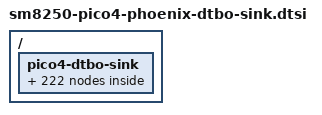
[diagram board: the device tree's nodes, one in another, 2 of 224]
// SPDX-License-Identifier: GPL-2.0-only
// Generated by dtbo_sink.py: absorbs the ABL's board overlay.

/ {
	pico4-dtbo-sink {
		pico4,refs = <&dtbo_BOB &dtbo_CPU4 &dtbo_CPU7 &dtbo_S4A &dtbo_apps_rsc &dtbo_apps_smmu &dtbo_arch_timer &dtbo_audio_apr &dtbo_bolero &dtbo_bt_en_sleep &dtbo_cam_cci0 &dtbo_cam_cci1 &dtbo_cam_sensor_6dof_vana_active &dtbo_cam_sensor_6dof_vana_suspend &dtbo_cam_sensor_6dof_vdig_active &dtbo_cam_sensor_6dof_vdig_suspend &dtbo_cam_sensor_6dof_vio_active &dtbo_cam_sensor_6dof_vio_suspend &dtbo_cam_sensor_active_3 &dtbo_cam_sensor_active_6 &dtbo_cam_sensor_active_6dofleft &dtbo_cam_sensor_active_6dofright &dtbo_cam_sensor_active_etleft &dtbo_cam_sensor_active_etright &dtbo_cam_sensor_active_rear &dtbo_cam_sensor_active_rear_aux &dtbo_cam_sensor_active_rgbleft &dtbo_cam_sensor_active_rgbright &dtbo_cam_sensor_active_rst2 &dtbo_cam_sensor_et_vana_active &dtbo_cam_sensor_et_vana_suspend &dtbo_cam_sensor_et_vio_active &dtbo_cam_sensor_et_vio_suspend &dtbo_cam_sensor_mclk0_active &dtbo_cam_sensor_mclk0_suspend &dtbo_cam_sensor_mclk1_active &dtbo_cam_sensor_mclk1_suspend &dtbo_cam_sensor_mclk2_active &dtbo_cam_sensor_mclk2_suspend &dtbo_cam_sensor_mclk3_active &dtbo_cam_sensor_mclk3_suspend &dtbo_cam_sensor_mclk4_active &dtbo_cam_sensor_mclk4_suspend &dtbo_cam_sensor_mclk5_active &dtbo_cam_sensor_mclk5_suspend &dtbo_cam_sensor_mclk6_active &dtbo_cam_sensor_mclk6_suspend &dtbo_cam_sensor_rgb_vana_active &dtbo_cam_sensor_rgb_vana_suspend &dtbo_cam_sensor_rgb_vdig_active &dtbo_cam_sensor_rgb_vdig_suspend &dtbo_cam_sensor_rgb_vio_active &dtbo_cam_sensor_rgb_vio_suspend &dtbo_cam_sensor_suspend_3 &dtbo_cam_sensor_suspend_6 &dtbo_cam_sensor_suspend_6dofleft &dtbo_cam_sensor_suspend_6dofright &dtbo_cam_sensor_suspend_etleft &dtbo_cam_sensor_suspend_etright &dtbo_cam_sensor_suspend_rear &dtbo_cam_sensor_suspend_rear_aux &dtbo_cam_sensor_suspend_rgbleft &dtbo_cam_sensor_suspend_rgbright &dtbo_cam_sensor_suspend_rst2 &dtbo_clock_camcc &dtbo_clock_rpmh &dtbo_cpu4_isolate &dtbo_cpu5_isolate &dtbo_cpu6_isolate &dtbo_cpu7_isolate &dtbo_dai_mi2s0 &dtbo_dai_mi2s2 &dtbo_dai_mi2s3 &dtbo_dwc1 &dtbo_eud &dtbo_fsa4480 &dtbo_intc &dtbo_ipa_hw &dtbo_kona_snd &dtbo_lpass_audio_hw_vote &dtbo_lpass_core_hw_vote &dtbo_lt9611_pins &dtbo_mdm0 &dtbo_mdss_dsi0 &dtbo_mdss_dsi0_pll &dtbo_mdss_dsi1 &dtbo_mdss_dsi1_pll &dtbo_mdss_dsi_phy0 &dtbo_mdss_dsi_phy1 &dtbo_mdss_mdp &dtbo_memtimer &dtbo_mhi_0 &dtbo_modem_mmw_skin0 &dtbo_modem_mmw_skin1 &dtbo_modem_mmw_skin2 &dtbo_modem_skin &dtbo_msm_gpu &dtbo_nfc_clk_req_active &dtbo_nfc_clk_req_suspend &dtbo_nfc_enable_active &dtbo_nfc_enable_suspend &dtbo_nfc_int_active &dtbo_nfc_int_suspend &dtbo_pcie0 &dtbo_pcie1 &dtbo_pcie2 &dtbo_pdc &dtbo_pm8009_l1 &dtbo_pm8009_l2 &dtbo_pm8009_l3 &dtbo_pm8009_l5 &dtbo_pm8009_l6 &dtbo_pm8009_l7 &dtbo_pm8009_s2 &dtbo_pm8150_l10 &dtbo_pm8150_l13 &dtbo_pm8150_l14 &dtbo_pm8150_l15 &dtbo_pm8150_l16 &dtbo_pm8150_l17 &dtbo_pm8150_l2 &dtbo_pm8150_l5 &dtbo_pm8150_l6 &dtbo_pm8150_l7 &dtbo_pm8150_l9 &dtbo_pm8150_s4 &dtbo_pm8150_s5 &dtbo_pm8150_s6 &dtbo_pm8150a_bob &dtbo_pm8150a_l1 &dtbo_pm8150a_l10 &dtbo_pm8150a_l11 &dtbo_pm8150a_l2 &dtbo_pm8150a_l3 &dtbo_pm8150a_l4 &dtbo_pm8150a_l5 &dtbo_pm8150a_l6 &dtbo_pm8150a_l7 &dtbo_pm8150a_l8 &dtbo_pm8150a_l9 &dtbo_pm8150a_s8 &dtbo_pmx_ts_release &dtbo_pri_mi2s_sck_active &dtbo_pri_mi2s_sck_sleep &dtbo_pri_mi2s_sd0_active &dtbo_pri_mi2s_sd0_sleep &dtbo_pri_mi2s_sd1_active &dtbo_pri_mi2s_sd1_sleep &dtbo_pri_mi2s_ws_active &dtbo_pri_mi2s_ws_sleep &dtbo_q6core &dtbo_qupv3_se12_2uart &dtbo_qupv3_se13_i2c &dtbo_qupv3_se15_i2c &dtbo_qupv3_se16_4uart &dtbo_qupv3_se17_i2c &dtbo_qupv3_se19_spi &dtbo_qupv3_se1_2uart &dtbo_qupv3_se1_i2c &dtbo_qupv3_se2_2uart &dtbo_qupv3_se6_4uart &dtbo_sdc2_clk_off &dtbo_sdc2_clk_on &dtbo_sdc2_cmd_off &dtbo_sdc2_cmd_on &dtbo_sdc2_data_off &dtbo_sdc2_data_on &dtbo_sde_dp &dtbo_sde_dp_aux_active_v0 &dtbo_sde_dp_aux_active_v1 &dtbo_sde_dp_aux_suspend_v0 &dtbo_sde_dp_aux_suspend_v1 &dtbo_sde_dp_usbplug_cc_active &dtbo_sde_dp_usbplug_cc_suspend &dtbo_sde_dsi1_active &dtbo_sde_dsi1_suspend &dtbo_sde_dsi_active &dtbo_sde_dsi_suspend &dtbo_sde_rscc &dtbo_sde_te1_active &dtbo_sde_te1_suspend &dtbo_sde_te_active &dtbo_sde_te_suspend &dtbo_sdhc_2 &dtbo_soc &dtbo_spkr_1_sd_n_active &dtbo_spkr_1_sd_n_sleep &dtbo_spkr_2_sd_n_active &dtbo_spkr_2_sd_n_sleep &dtbo_spmi_bus &dtbo_spmi_debug_bus &dtbo_storage_cd &dtbo_stub_codec &dtbo_tert_mi2s_sck_active &dtbo_tert_mi2s_sck_sleep &dtbo_tert_mi2s_sd0_active &dtbo_tert_mi2s_sd0_sleep &dtbo_tert_mi2s_ws_active &dtbo_tert_mi2s_ws_sleep &dtbo_thermal_zones &dtbo_titan_top_gdsc &dtbo_tlmm &dtbo_tlmm_app_key_active &dtbo_tlmm_app_key_suspend &dtbo_ts_active &dtbo_ts_int_suspend &dtbo_ts_reset_suspend &dtbo_ufs_phy_gdsc &dtbo_ufshc_mem &dtbo_ufsphy_mem &dtbo_usb0 &dtbo_usb1 &dtbo_usb2_id_det_default &dtbo_usb2_phy0 &dtbo_usb_nop_phy &dtbo_va_cdc_dma_0_tx &dtbo_vendor &dtbo_wcd938x_reset_active &dtbo_wcd938x_reset_sleep &dtbo_wdog &dtbo_wil6210 &dtbo_wlan>;

		dtbo_BOB: BOB {
		};
		dtbo_CPU4: CPU4 {
		};
		dtbo_CPU7: CPU7 {
		};
		dtbo_S4A: S4A {
		};
		dtbo_apps_rsc: apps_rsc {
		};
		dtbo_apps_smmu: apps_smmu {
		};
		dtbo_arch_timer: arch_timer {
		};
		dtbo_audio_apr: audio_apr {
		};
		dtbo_bolero: bolero {
		};
		dtbo_bt_en_sleep: bt_en_sleep {
		};
		dtbo_cam_cci0: cam_cci0 {
		};
		dtbo_cam_cci1: cam_cci1 {
		};
		dtbo_cam_sensor_6dof_vana_active: cam_sensor_6dof_vana_active {
		};
		dtbo_cam_sensor_6dof_vana_suspend: cam_sensor_6dof_vana_suspend {
		};
		dtbo_cam_sensor_6dof_vdig_active: cam_sensor_6dof_vdig_active {
		};
		dtbo_cam_sensor_6dof_vdig_suspend: cam_sensor_6dof_vdig_suspend {
		};
		dtbo_cam_sensor_6dof_vio_active: cam_sensor_6dof_vio_active {
		};
		dtbo_cam_sensor_6dof_vio_suspend: cam_sensor_6dof_vio_suspend {
		};
		dtbo_cam_sensor_active_3: cam_sensor_active_3 {
		};
		dtbo_cam_sensor_active_6: cam_sensor_active_6 {
		};
		dtbo_cam_sensor_active_6dofleft: cam_sensor_active_6dofleft {
		};
		dtbo_cam_sensor_active_6dofright: cam_sensor_active_6dofright {
		};
		dtbo_cam_sensor_active_etleft: cam_sensor_active_etleft {
		};
		dtbo_cam_sensor_active_etright: cam_sensor_active_etright {
		};
		dtbo_cam_sensor_active_rear: cam_sensor_active_rear {
		};
		dtbo_cam_sensor_active_rear_aux: cam_sensor_active_rear_aux {
		};
		dtbo_cam_sensor_active_rgbleft: cam_sensor_active_rgbleft {
		};
		dtbo_cam_sensor_active_rgbright: cam_sensor_active_rgbright {
		};
		dtbo_cam_sensor_active_rst2: cam_sensor_active_rst2 {
		};
		dtbo_cam_sensor_et_vana_active: cam_sensor_et_vana_active {
		};
		dtbo_cam_sensor_et_vana_suspend: cam_sensor_et_vana_suspend {
		};
		dtbo_cam_sensor_et_vio_active: cam_sensor_et_vio_active {
		};
		dtbo_cam_sensor_et_vio_suspend: cam_sensor_et_vio_suspend {
		};
		dtbo_cam_sensor_mclk0_active: cam_sensor_mclk0_active {
		};
		dtbo_cam_sensor_mclk0_suspend: cam_sensor_mclk0_suspend {
		};
		dtbo_cam_sensor_mclk1_active: cam_sensor_mclk1_active {
		};
		dtbo_cam_sensor_mclk1_suspend: cam_sensor_mclk1_suspend {
		};
		dtbo_cam_sensor_mclk2_active: cam_sensor_mclk2_active {
		};
		dtbo_cam_sensor_mclk2_suspend: cam_sensor_mclk2_suspend {
		};
		dtbo_cam_sensor_mclk3_active: cam_sensor_mclk3_active {
		};
		dtbo_cam_sensor_mclk3_suspend: cam_sensor_mclk3_suspend {
		};
		dtbo_cam_sensor_mclk4_active: cam_sensor_mclk4_active {
		};
		dtbo_cam_sensor_mclk4_suspend: cam_sensor_mclk4_suspend {
		};
		dtbo_cam_sensor_mclk5_active: cam_sensor_mclk5_active {
		};
		dtbo_cam_sensor_mclk5_suspend: cam_sensor_mclk5_suspend {
		};
		dtbo_cam_sensor_mclk6_active: cam_sensor_mclk6_active {
		};
		dtbo_cam_sensor_mclk6_suspend: cam_sensor_mclk6_suspend {
		};
		dtbo_cam_sensor_rgb_vana_active: cam_sensor_rgb_vana_active {
		};
		dtbo_cam_sensor_rgb_vana_suspend: cam_sensor_rgb_vana_suspend {
		};
		dtbo_cam_sensor_rgb_vdig_active: cam_sensor_rgb_vdig_active {
		};
		dtbo_cam_sensor_rgb_vdig_suspend: cam_sensor_rgb_vdig_suspend {
		};
		dtbo_cam_sensor_rgb_vio_active: cam_sensor_rgb_vio_active {
		};
		dtbo_cam_sensor_rgb_vio_suspend: cam_sensor_rgb_vio_suspend {
		};
		dtbo_cam_sensor_suspend_3: cam_sensor_suspend_3 {
		};
		dtbo_cam_sensor_suspend_6: cam_sensor_suspend_6 {
		};
		dtbo_cam_sensor_suspend_6dofleft: cam_sensor_suspend_6dofleft {
		};
		dtbo_cam_sensor_suspend_6dofright: cam_sensor_suspend_6dofright {
		};
		dtbo_cam_sensor_suspend_etleft: cam_sensor_suspend_etleft {
		};
		dtbo_cam_sensor_suspend_etright: cam_sensor_suspend_etright {
		};
		dtbo_cam_sensor_suspend_rear: cam_sensor_suspend_rear {
		};
		dtbo_cam_sensor_suspend_rear_aux: cam_sensor_suspend_rear_aux {
		};
		dtbo_cam_sensor_suspend_rgbleft: cam_sensor_suspend_rgbleft {
		};
		dtbo_cam_sensor_suspend_rgbright: cam_sensor_suspend_rgbright {
		};
		dtbo_cam_sensor_suspend_rst2: cam_sensor_suspend_rst2 {
		};
		dtbo_clock_camcc: clock_camcc {
		};
		dtbo_clock_rpmh: clock_rpmh {
		};
		dtbo_cpu4_isolate: cpu4_isolate {
		};
		dtbo_cpu5_isolate: cpu5_isolate {
		};
		dtbo_cpu6_isolate: cpu6_isolate {
		};
		dtbo_cpu7_isolate: cpu7_isolate {
		};
		dtbo_dai_mi2s0: dai_mi2s0 {
		};
		dtbo_dai_mi2s2: dai_mi2s2 {
		};
		dtbo_dai_mi2s3: dai_mi2s3 {
		};
		dtbo_dwc1: dwc1 {
		};
		dtbo_eud: eud {
		};
		dtbo_fsa4480: fsa4480 {
		};
		dtbo_intc: intc {
		};
		dtbo_ipa_hw: ipa_hw {
		};
		dtbo_kona_snd: kona_snd {
		};
		dtbo_lpass_audio_hw_vote: lpass_audio_hw_vote {
		};
		dtbo_lpass_core_hw_vote: lpass_core_hw_vote {
		};
		dtbo_lt9611_pins: lt9611_pins {
		};
		dtbo_mdm0: mdm0 {
		};
		dtbo_mdss_dsi0: mdss_dsi0 {
		};
		dtbo_mdss_dsi0_pll: mdss_dsi0_pll {
		};
		dtbo_mdss_dsi1: mdss_dsi1 {
		};
		dtbo_mdss_dsi1_pll: mdss_dsi1_pll {
		};
		dtbo_mdss_dsi_phy0: mdss_dsi_phy0 {
		};
		dtbo_mdss_dsi_phy1: mdss_dsi_phy1 {
		};
		dtbo_mdss_mdp: mdss_mdp {
		};
		dtbo_memtimer: memtimer {
		};
		dtbo_mhi_0: mhi_0 {
		};
		dtbo_modem_mmw_skin0: modem_mmw_skin0 {
		};
		dtbo_modem_mmw_skin1: modem_mmw_skin1 {
		};
		dtbo_modem_mmw_skin2: modem_mmw_skin2 {
		};
		dtbo_modem_skin: modem_skin {
		};
		dtbo_msm_gpu: msm_gpu {
		};
		dtbo_nfc_clk_req_active: nfc_clk_req_active {
		};
		dtbo_nfc_clk_req_suspend: nfc_clk_req_suspend {
		};
		dtbo_nfc_enable_active: nfc_enable_active {
		};
		dtbo_nfc_enable_suspend: nfc_enable_suspend {
		};
		dtbo_nfc_int_active: nfc_int_active {
		};
		dtbo_nfc_int_suspend: nfc_int_suspend {
		};
		dtbo_pcie0: pcie0 {
		};
		dtbo_pcie1: pcie1 {
		};
		dtbo_pcie2: pcie2 {
		};
		dtbo_pdc: pdc {
		};
		dtbo_pm8009_l1: pm8009_l1 {
		};
		dtbo_pm8009_l2: pm8009_l2 {
		};
		dtbo_pm8009_l3: pm8009_l3 {
		};
		dtbo_pm8009_l5: pm8009_l5 {
		};
		dtbo_pm8009_l6: pm8009_l6 {
		};
		dtbo_pm8009_l7: pm8009_l7 {
		};
		dtbo_pm8009_s2: pm8009_s2 {
		};
		dtbo_pm8150_l10: pm8150_l10 {
		};
		dtbo_pm8150_l13: pm8150_l13 {
		};
		dtbo_pm8150_l14: pm8150_l14 {
		};
		dtbo_pm8150_l15: pm8150_l15 {
		};
		dtbo_pm8150_l16: pm8150_l16 {
		};
		dtbo_pm8150_l17: pm8150_l17 {
		};
		dtbo_pm8150_l2: pm8150_l2 {
		};
		dtbo_pm8150_l5: pm8150_l5 {
		};
		dtbo_pm8150_l6: pm8150_l6 {
		};
		dtbo_pm8150_l7: pm8150_l7 {
		};
		dtbo_pm8150_l9: pm8150_l9 {
		};
		dtbo_pm8150_s4: pm8150_s4 {
		};
		dtbo_pm8150_s5: pm8150_s5 {
		};
		dtbo_pm8150_s6: pm8150_s6 {
		};
		dtbo_pm8150a_bob: pm8150a_bob {
		};
		dtbo_pm8150a_l1: pm8150a_l1 {
		};
		dtbo_pm8150a_l10: pm8150a_l10 {
		};
		dtbo_pm8150a_l11: pm8150a_l11 {
		};
		dtbo_pm8150a_l2: pm8150a_l2 {
		};
		dtbo_pm8150a_l3: pm8150a_l3 {
		};
		dtbo_pm8150a_l4: pm8150a_l4 {
		};
		dtbo_pm8150a_l5: pm8150a_l5 {
		};
		dtbo_pm8150a_l6: pm8150a_l6 {
		};
		dtbo_pm8150a_l7: pm8150a_l7 {
		};
		dtbo_pm8150a_l8: pm8150a_l8 {
		};
		dtbo_pm8150a_l9: pm8150a_l9 {
		};
		dtbo_pm8150a_s8: pm8150a_s8 {
		};
		dtbo_pmx_ts_release: pmx_ts_release {
		};
		dtbo_pri_mi2s_sck_active: pri_mi2s_sck_active {
		};
		dtbo_pri_mi2s_sck_sleep: pri_mi2s_sck_sleep {
		};
		dtbo_pri_mi2s_sd0_active: pri_mi2s_sd0_active {
		};
		dtbo_pri_mi2s_sd0_sleep: pri_mi2s_sd0_sleep {
		};
		dtbo_pri_mi2s_sd1_active: pri_mi2s_sd1_active {
		};
		dtbo_pri_mi2s_sd1_sleep: pri_mi2s_sd1_sleep {
		};
		dtbo_pri_mi2s_ws_active: pri_mi2s_ws_active {
		};
		dtbo_pri_mi2s_ws_sleep: pri_mi2s_ws_sleep {
		};
		dtbo_q6core: q6core {
		};
		dtbo_qupv3_se12_2uart: qupv3_se12_2uart {
		};
		dtbo_qupv3_se13_i2c: qupv3_se13_i2c {
		};
		dtbo_qupv3_se15_i2c: qupv3_se15_i2c {
		};
		dtbo_qupv3_se16_4uart: qupv3_se16_4uart {
		};
		dtbo_qupv3_se17_i2c: qupv3_se17_i2c {
		};
		dtbo_qupv3_se19_spi: qupv3_se19_spi {
		};
		dtbo_qupv3_se1_2uart: qupv3_se1_2uart {
		};
		dtbo_qupv3_se1_i2c: qupv3_se1_i2c {
		};
		dtbo_qupv3_se2_2uart: qupv3_se2_2uart {
		};
		dtbo_qupv3_se6_4uart: qupv3_se6_4uart {
		};
		dtbo_sdc2_clk_off: sdc2_clk_off {
		};
		dtbo_sdc2_clk_on: sdc2_clk_on {
		};
		dtbo_sdc2_cmd_off: sdc2_cmd_off {
		};
		dtbo_sdc2_cmd_on: sdc2_cmd_on {
		};
		dtbo_sdc2_data_off: sdc2_data_off {
		};
		dtbo_sdc2_data_on: sdc2_data_on {
		};
		dtbo_sde_dp: sde_dp {
		};
		dtbo_sde_dp_aux_active_v0: sde_dp_aux_active_v0 {
		};
		dtbo_sde_dp_aux_active_v1: sde_dp_aux_active_v1 {
		};
		dtbo_sde_dp_aux_suspend_v0: sde_dp_aux_suspend_v0 {
		};
		dtbo_sde_dp_aux_suspend_v1: sde_dp_aux_suspend_v1 {
		};
		dtbo_sde_dp_usbplug_cc_active: sde_dp_usbplug_cc_active {
		};
		dtbo_sde_dp_usbplug_cc_suspend: sde_dp_usbplug_cc_suspend {
		};
		dtbo_sde_dsi1_active: sde_dsi1_active {
		};
		dtbo_sde_dsi1_suspend: sde_dsi1_suspend {
		};
		dtbo_sde_dsi_active: sde_dsi_active {
		};
		dtbo_sde_dsi_suspend: sde_dsi_suspend {
		};
		dtbo_sde_rscc: sde_rscc {
		};
		dtbo_sde_te1_active: sde_te1_active {
		};
		dtbo_sde_te1_suspend: sde_te1_suspend {
		};
		dtbo_sde_te_active: sde_te_active {
		};
		dtbo_sde_te_suspend: sde_te_suspend {
		};
		dtbo_sdhc_2: sdhc_2 {
		};
		dtbo_soc: soc {
		};
		dtbo_spkr_1_sd_n_active: spkr_1_sd_n_active {
		};
		dtbo_spkr_1_sd_n_sleep: spkr_1_sd_n_sleep {
		};
		dtbo_spkr_2_sd_n_active: spkr_2_sd_n_active {
		};
		dtbo_spkr_2_sd_n_sleep: spkr_2_sd_n_sleep {
		};
		dtbo_spmi_bus: spmi_bus {
		};
		dtbo_spmi_debug_bus: spmi_debug_bus {
		};
		dtbo_storage_cd: storage_cd {
		};
		dtbo_stub_codec: stub_codec {
		};
		dtbo_tert_mi2s_sck_active: tert_mi2s_sck_active {
		};
		dtbo_tert_mi2s_sck_sleep: tert_mi2s_sck_sleep {
		};
		dtbo_tert_mi2s_sd0_active: tert_mi2s_sd0_active {
		};
		dtbo_tert_mi2s_sd0_sleep: tert_mi2s_sd0_sleep {
		};
		dtbo_tert_mi2s_ws_active: tert_mi2s_ws_active {
		};
		dtbo_tert_mi2s_ws_sleep: tert_mi2s_ws_sleep {
		};
		dtbo_thermal_zones: thermal_zones {
		};
		dtbo_titan_top_gdsc: titan_top_gdsc {
		};
		dtbo_tlmm: tlmm {
		};
		dtbo_tlmm_app_key_active: tlmm_app_key_active {
		};
		dtbo_tlmm_app_key_suspend: tlmm_app_key_suspend {
		};
		dtbo_ts_active: ts_active {
		};
		dtbo_ts_int_suspend: ts_int_suspend {
		};
		dtbo_ts_reset_suspend: ts_reset_suspend {
		};
		dtbo_ufs_phy_gdsc: ufs_phy_gdsc {
		};
		dtbo_ufshc_mem: ufshc_mem {
		};
		dtbo_ufsphy_mem: ufsphy_mem {
		};
		dtbo_usb0: usb0 {
		};
		dtbo_usb1: usb1 {
		};
		dtbo_usb2_id_det_default: usb2_id_det_default {
		};
		dtbo_usb2_phy0: usb2_phy0 {
		};
		dtbo_usb_nop_phy: usb_nop_phy {
		};
		dtbo_va_cdc_dma_0_tx: va_cdc_dma_0_tx {
		};
		dtbo_vendor: vendor {
		};
		dtbo_wcd938x_reset_active: wcd938x_reset_active {
		};
		dtbo_wcd938x_reset_sleep: wcd938x_reset_sleep {
		};
		dtbo_wdog: wdog {
		};
		dtbo_wil6210: wil6210 {
		};
		dtbo_wlan: wlan {
		};
	};

	__symbols__ {
		BOB = "/pico4-dtbo-sink/BOB";
		CPU4 = "/pico4-dtbo-sink/CPU4";
		CPU7 = "/pico4-dtbo-sink/CPU7";
		S4A = "/pico4-dtbo-sink/S4A";
		apps_rsc = "/pico4-dtbo-sink/apps_rsc";
		apps_smmu = "/pico4-dtbo-sink/apps_smmu";
		arch_timer = "/pico4-dtbo-sink/arch_timer";
		audio_apr = "/pico4-dtbo-sink/audio_apr";
		bolero = "/pico4-dtbo-sink/bolero";
		bt_en_sleep = "/pico4-dtbo-sink/bt_en_sleep";
		cam_cci0 = "/pico4-dtbo-sink/cam_cci0";
		cam_cci1 = "/pico4-dtbo-sink/cam_cci1";
		cam_sensor_6dof_vana_active = "/pico4-dtbo-sink/cam_sensor_6dof_vana_active";
		cam_sensor_6dof_vana_suspend = "/pico4-dtbo-sink/cam_sensor_6dof_vana_suspend";
		cam_sensor_6dof_vdig_active = "/pico4-dtbo-sink/cam_sensor_6dof_vdig_active";
		cam_sensor_6dof_vdig_suspend = "/pico4-dtbo-sink/cam_sensor_6dof_vdig_suspend";
		cam_sensor_6dof_vio_active = "/pico4-dtbo-sink/cam_sensor_6dof_vio_active";
		cam_sensor_6dof_vio_suspend = "/pico4-dtbo-sink/cam_sensor_6dof_vio_suspend";
		cam_sensor_active_3 = "/pico4-dtbo-sink/cam_sensor_active_3";
		cam_sensor_active_6 = "/pico4-dtbo-sink/cam_sensor_active_6";
		cam_sensor_active_6dofleft = "/pico4-dtbo-sink/cam_sensor_active_6dofleft";
		cam_sensor_active_6dofright = "/pico4-dtbo-sink/cam_sensor_active_6dofright";
		cam_sensor_active_etleft = "/pico4-dtbo-sink/cam_sensor_active_etleft";
		cam_sensor_active_etright = "/pico4-dtbo-sink/cam_sensor_active_etright";
		cam_sensor_active_rear = "/pico4-dtbo-sink/cam_sensor_active_rear";
		cam_sensor_active_rear_aux = "/pico4-dtbo-sink/cam_sensor_active_rear_aux";
		cam_sensor_active_rgbleft = "/pico4-dtbo-sink/cam_sensor_active_rgbleft";
		cam_sensor_active_rgbright = "/pico4-dtbo-sink/cam_sensor_active_rgbright";
		cam_sensor_active_rst2 = "/pico4-dtbo-sink/cam_sensor_active_rst2";
		cam_sensor_et_vana_active = "/pico4-dtbo-sink/cam_sensor_et_vana_active";
		cam_sensor_et_vana_suspend = "/pico4-dtbo-sink/cam_sensor_et_vana_suspend";
		cam_sensor_et_vio_active = "/pico4-dtbo-sink/cam_sensor_et_vio_active";
		cam_sensor_et_vio_suspend = "/pico4-dtbo-sink/cam_sensor_et_vio_suspend";
		cam_sensor_mclk0_active = "/pico4-dtbo-sink/cam_sensor_mclk0_active";
		cam_sensor_mclk0_suspend = "/pico4-dtbo-sink/cam_sensor_mclk0_suspend";
		cam_sensor_mclk1_active = "/pico4-dtbo-sink/cam_sensor_mclk1_active";
		cam_sensor_mclk1_suspend = "/pico4-dtbo-sink/cam_sensor_mclk1_suspend";
		cam_sensor_mclk2_active = "/pico4-dtbo-sink/cam_sensor_mclk2_active";
		cam_sensor_mclk2_suspend = "/pico4-dtbo-sink/cam_sensor_mclk2_suspend";
		cam_sensor_mclk3_active = "/pico4-dtbo-sink/cam_sensor_mclk3_active";
		cam_sensor_mclk3_suspend = "/pico4-dtbo-sink/cam_sensor_mclk3_suspend";
		cam_sensor_mclk4_active = "/pico4-dtbo-sink/cam_sensor_mclk4_active";
		cam_sensor_mclk4_suspend = "/pico4-dtbo-sink/cam_sensor_mclk4_suspend";
		cam_sensor_mclk5_active = "/pico4-dtbo-sink/cam_sensor_mclk5_active";
		cam_sensor_mclk5_suspend = "/pico4-dtbo-sink/cam_sensor_mclk5_suspend";
		cam_sensor_mclk6_active = "/pico4-dtbo-sink/cam_sensor_mclk6_active";
		cam_sensor_mclk6_suspend = "/pico4-dtbo-sink/cam_sensor_mclk6_suspend";
		cam_sensor_rgb_vana_active = "/pico4-dtbo-sink/cam_sensor_rgb_vana_active";
		cam_sensor_rgb_vana_suspend = "/pico4-dtbo-sink/cam_sensor_rgb_vana_suspend";
		cam_sensor_rgb_vdig_active = "/pico4-dtbo-sink/cam_sensor_rgb_vdig_active";
		cam_sensor_rgb_vdig_suspend = "/pico4-dtbo-sink/cam_sensor_rgb_vdig_suspend";
		cam_sensor_rgb_vio_active = "/pico4-dtbo-sink/cam_sensor_rgb_vio_active";
		cam_sensor_rgb_vio_suspend = "/pico4-dtbo-sink/cam_sensor_rgb_vio_suspend";
		cam_sensor_suspend_3 = "/pico4-dtbo-sink/cam_sensor_suspend_3";
		cam_sensor_suspend_6 = "/pico4-dtbo-sink/cam_sensor_suspend_6";
		cam_sensor_suspend_6dofleft = "/pico4-dtbo-sink/cam_sensor_suspend_6dofleft";
		cam_sensor_suspend_6dofright = "/pico4-dtbo-sink/cam_sensor_suspend_6dofright";
		cam_sensor_suspend_etleft = "/pico4-dtbo-sink/cam_sensor_suspend_etleft";
		cam_sensor_suspend_etright = "/pico4-dtbo-sink/cam_sensor_suspend_etright";
		cam_sensor_suspend_rear = "/pico4-dtbo-sink/cam_sensor_suspend_rear";
		cam_sensor_suspend_rear_aux = "/pico4-dtbo-sink/cam_sensor_suspend_rear_aux";
		cam_sensor_suspend_rgbleft = "/pico4-dtbo-sink/cam_sensor_suspend_rgbleft";
		cam_sensor_suspend_rgbright = "/pico4-dtbo-sink/cam_sensor_suspend_rgbright";
		cam_sensor_suspend_rst2 = "/pico4-dtbo-sink/cam_sensor_suspend_rst2";
		clock_camcc = "/pico4-dtbo-sink/clock_camcc";
		clock_rpmh = "/pico4-dtbo-sink/clock_rpmh";
		cpu4_isolate = "/pico4-dtbo-sink/cpu4_isolate";
		cpu5_isolate = "/pico4-dtbo-sink/cpu5_isolate";
		cpu6_isolate = "/pico4-dtbo-sink/cpu6_isolate";
		cpu7_isolate = "/pico4-dtbo-sink/cpu7_isolate";
		dai_mi2s0 = "/pico4-dtbo-sink/dai_mi2s0";
		dai_mi2s2 = "/pico4-dtbo-sink/dai_mi2s2";
		dai_mi2s3 = "/pico4-dtbo-sink/dai_mi2s3";
		dwc1 = "/pico4-dtbo-sink/dwc1";
		eud = "/pico4-dtbo-sink/eud";
		fsa4480 = "/pico4-dtbo-sink/fsa4480";
		intc = "/pico4-dtbo-sink/intc";
		ipa_hw = "/pico4-dtbo-sink/ipa_hw";
		kona_snd = "/pico4-dtbo-sink/kona_snd";
		lpass_audio_hw_vote = "/pico4-dtbo-sink/lpass_audio_hw_vote";
		lpass_core_hw_vote = "/pico4-dtbo-sink/lpass_core_hw_vote";
		lt9611_pins = "/pico4-dtbo-sink/lt9611_pins";
		mdm0 = "/pico4-dtbo-sink/mdm0";
		mdss_dsi0 = "/pico4-dtbo-sink/mdss_dsi0";
		mdss_dsi0_pll = "/pico4-dtbo-sink/mdss_dsi0_pll";
		mdss_dsi1 = "/pico4-dtbo-sink/mdss_dsi1";
		mdss_dsi1_pll = "/pico4-dtbo-sink/mdss_dsi1_pll";
		mdss_dsi_phy0 = "/pico4-dtbo-sink/mdss_dsi_phy0";
		mdss_dsi_phy1 = "/pico4-dtbo-sink/mdss_dsi_phy1";
		mdss_mdp = "/pico4-dtbo-sink/mdss_mdp";
		memtimer = "/pico4-dtbo-sink/memtimer";
		mhi_0 = "/pico4-dtbo-sink/mhi_0";
		modem_mmw_skin0 = "/pico4-dtbo-sink/modem_mmw_skin0";
		modem_mmw_skin1 = "/pico4-dtbo-sink/modem_mmw_skin1";
		modem_mmw_skin2 = "/pico4-dtbo-sink/modem_mmw_skin2";
		modem_skin = "/pico4-dtbo-sink/modem_skin";
		msm_gpu = "/pico4-dtbo-sink/msm_gpu";
		nfc_clk_req_active = "/pico4-dtbo-sink/nfc_clk_req_active";
		nfc_clk_req_suspend = "/pico4-dtbo-sink/nfc_clk_req_suspend";
		nfc_enable_active = "/pico4-dtbo-sink/nfc_enable_active";
		nfc_enable_suspend = "/pico4-dtbo-sink/nfc_enable_suspend";
		nfc_int_active = "/pico4-dtbo-sink/nfc_int_active";
		nfc_int_suspend = "/pico4-dtbo-sink/nfc_int_suspend";
		pcie0 = "/pico4-dtbo-sink/pcie0";
		pcie1 = "/pico4-dtbo-sink/pcie1";
		pcie2 = "/pico4-dtbo-sink/pcie2";
		pdc = "/pico4-dtbo-sink/pdc";
		pm8009_l1 = "/pico4-dtbo-sink/pm8009_l1";
		pm8009_l2 = "/pico4-dtbo-sink/pm8009_l2";
		pm8009_l3 = "/pico4-dtbo-sink/pm8009_l3";
		pm8009_l5 = "/pico4-dtbo-sink/pm8009_l5";
		pm8009_l6 = "/pico4-dtbo-sink/pm8009_l6";
		pm8009_l7 = "/pico4-dtbo-sink/pm8009_l7";
		pm8009_s2 = "/pico4-dtbo-sink/pm8009_s2";
		pm8150_l10 = "/pico4-dtbo-sink/pm8150_l10";
		pm8150_l13 = "/pico4-dtbo-sink/pm8150_l13";
		pm8150_l14 = "/pico4-dtbo-sink/pm8150_l14";
		pm8150_l15 = "/pico4-dtbo-sink/pm8150_l15";
		pm8150_l16 = "/pico4-dtbo-sink/pm8150_l16";
		pm8150_l17 = "/pico4-dtbo-sink/pm8150_l17";
		pm8150_l2 = "/pico4-dtbo-sink/pm8150_l2";
		pm8150_l5 = "/pico4-dtbo-sink/pm8150_l5";
		pm8150_l6 = "/pico4-dtbo-sink/pm8150_l6";
		pm8150_l7 = "/pico4-dtbo-sink/pm8150_l7";
		pm8150_l9 = "/pico4-dtbo-sink/pm8150_l9";
		pm8150_s4 = "/pico4-dtbo-sink/pm8150_s4";
		pm8150_s5 = "/pico4-dtbo-sink/pm8150_s5";
		pm8150_s6 = "/pico4-dtbo-sink/pm8150_s6";
		pm8150a_bob = "/pico4-dtbo-sink/pm8150a_bob";
		pm8150a_l1 = "/pico4-dtbo-sink/pm8150a_l1";
		pm8150a_l10 = "/pico4-dtbo-sink/pm8150a_l10";
		pm8150a_l11 = "/pico4-dtbo-sink/pm8150a_l11";
		pm8150a_l2 = "/pico4-dtbo-sink/pm8150a_l2";
		pm8150a_l3 = "/pico4-dtbo-sink/pm8150a_l3";
		pm8150a_l4 = "/pico4-dtbo-sink/pm8150a_l4";
		pm8150a_l5 = "/pico4-dtbo-sink/pm8150a_l5";
		pm8150a_l6 = "/pico4-dtbo-sink/pm8150a_l6";
		pm8150a_l7 = "/pico4-dtbo-sink/pm8150a_l7";
		pm8150a_l8 = "/pico4-dtbo-sink/pm8150a_l8";
		pm8150a_l9 = "/pico4-dtbo-sink/pm8150a_l9";
		pm8150a_s8 = "/pico4-dtbo-sink/pm8150a_s8";
		pmx_ts_release = "/pico4-dtbo-sink/pmx_ts_release";
		pri_mi2s_sck_active = "/pico4-dtbo-sink/pri_mi2s_sck_active";
		pri_mi2s_sck_sleep = "/pico4-dtbo-sink/pri_mi2s_sck_sleep";
		pri_mi2s_sd0_active = "/pico4-dtbo-sink/pri_mi2s_sd0_active";
		pri_mi2s_sd0_sleep = "/pico4-dtbo-sink/pri_mi2s_sd0_sleep";
		pri_mi2s_sd1_active = "/pico4-dtbo-sink/pri_mi2s_sd1_active";
		pri_mi2s_sd1_sleep = "/pico4-dtbo-sink/pri_mi2s_sd1_sleep";
		pri_mi2s_ws_active = "/pico4-dtbo-sink/pri_mi2s_ws_active";
		pri_mi2s_ws_sleep = "/pico4-dtbo-sink/pri_mi2s_ws_sleep";
		q6core = "/pico4-dtbo-sink/q6core";
		qupv3_se12_2uart = "/pico4-dtbo-sink/qupv3_se12_2uart";
		qupv3_se13_i2c = "/pico4-dtbo-sink/qupv3_se13_i2c";
		qupv3_se15_i2c = "/pico4-dtbo-sink/qupv3_se15_i2c";
		qupv3_se16_4uart = "/pico4-dtbo-sink/qupv3_se16_4uart";
		qupv3_se17_i2c = "/pico4-dtbo-sink/qupv3_se17_i2c";
		qupv3_se19_spi = "/pico4-dtbo-sink/qupv3_se19_spi";
		qupv3_se1_2uart = "/pico4-dtbo-sink/qupv3_se1_2uart";
		qupv3_se1_i2c = "/pico4-dtbo-sink/qupv3_se1_i2c";
		qupv3_se2_2uart = "/pico4-dtbo-sink/qupv3_se2_2uart";
		qupv3_se6_4uart = "/pico4-dtbo-sink/qupv3_se6_4uart";
		sdc2_clk_off = "/pico4-dtbo-sink/sdc2_clk_off";
		sdc2_clk_on = "/pico4-dtbo-sink/sdc2_clk_on";
		sdc2_cmd_off = "/pico4-dtbo-sink/sdc2_cmd_off";
		sdc2_cmd_on = "/pico4-dtbo-sink/sdc2_cmd_on";
		sdc2_data_off = "/pico4-dtbo-sink/sdc2_data_off";
		sdc2_data_on = "/pico4-dtbo-sink/sdc2_data_on";
		sde_dp = "/pico4-dtbo-sink/sde_dp";
		sde_dp_aux_active_v0 = "/pico4-dtbo-sink/sde_dp_aux_active_v0";
		sde_dp_aux_active_v1 = "/pico4-dtbo-sink/sde_dp_aux_active_v1";
		sde_dp_aux_suspend_v0 = "/pico4-dtbo-sink/sde_dp_aux_suspend_v0";
		sde_dp_aux_suspend_v1 = "/pico4-dtbo-sink/sde_dp_aux_suspend_v1";
		sde_dp_usbplug_cc_active = "/pico4-dtbo-sink/sde_dp_usbplug_cc_active";
		sde_dp_usbplug_cc_suspend = "/pico4-dtbo-sink/sde_dp_usbplug_cc_suspend";
		sde_dsi1_active = "/pico4-dtbo-sink/sde_dsi1_active";
		sde_dsi1_suspend = "/pico4-dtbo-sink/sde_dsi1_suspend";
		sde_dsi_active = "/pico4-dtbo-sink/sde_dsi_active";
		sde_dsi_suspend = "/pico4-dtbo-sink/sde_dsi_suspend";
		sde_rscc = "/pico4-dtbo-sink/sde_rscc";
		sde_te1_active = "/pico4-dtbo-sink/sde_te1_active";
		sde_te1_suspend = "/pico4-dtbo-sink/sde_te1_suspend";
		sde_te_active = "/pico4-dtbo-sink/sde_te_active";
		sde_te_suspend = "/pico4-dtbo-sink/sde_te_suspend";
		sdhc_2 = "/pico4-dtbo-sink/sdhc_2";
		soc = "/pico4-dtbo-sink/soc";
		spkr_1_sd_n_active = "/pico4-dtbo-sink/spkr_1_sd_n_active";
		spkr_1_sd_n_sleep = "/pico4-dtbo-sink/spkr_1_sd_n_sleep";
		spkr_2_sd_n_active = "/pico4-dtbo-sink/spkr_2_sd_n_active";
		spkr_2_sd_n_sleep = "/pico4-dtbo-sink/spkr_2_sd_n_sleep";
		spmi_bus = "/pico4-dtbo-sink/spmi_bus";
		spmi_debug_bus = "/pico4-dtbo-sink/spmi_debug_bus";
		storage_cd = "/pico4-dtbo-sink/storage_cd";
		stub_codec = "/pico4-dtbo-sink/stub_codec";
		tert_mi2s_sck_active = "/pico4-dtbo-sink/tert_mi2s_sck_active";
		tert_mi2s_sck_sleep = "/pico4-dtbo-sink/tert_mi2s_sck_sleep";
		tert_mi2s_sd0_active = "/pico4-dtbo-sink/tert_mi2s_sd0_active";
		tert_mi2s_sd0_sleep = "/pico4-dtbo-sink/tert_mi2s_sd0_sleep";
		tert_mi2s_ws_active = "/pico4-dtbo-sink/tert_mi2s_ws_active";
		tert_mi2s_ws_sleep = "/pico4-dtbo-sink/tert_mi2s_ws_sleep";
		thermal_zones = "/pico4-dtbo-sink/thermal_zones";
		titan_top_gdsc = "/pico4-dtbo-sink/titan_top_gdsc";
		tlmm = "/pico4-dtbo-sink/tlmm";
		tlmm_app_key_active = "/pico4-dtbo-sink/tlmm_app_key_active";
		tlmm_app_key_suspend = "/pico4-dtbo-sink/tlmm_app_key_suspend";
		ts_active = "/pico4-dtbo-sink/ts_active";
		ts_int_suspend = "/pico4-dtbo-sink/ts_int_suspend";
		ts_reset_suspend = "/pico4-dtbo-sink/ts_reset_suspend";
		ufs_phy_gdsc = "/pico4-dtbo-sink/ufs_phy_gdsc";
		ufshc_mem = "/pico4-dtbo-sink/ufshc_mem";
		ufsphy_mem = "/pico4-dtbo-sink/ufsphy_mem";
		usb0 = "/pico4-dtbo-sink/usb0";
		usb1 = "/pico4-dtbo-sink/usb1";
		usb2_id_det_default = "/pico4-dtbo-sink/usb2_id_det_default";
		usb2_phy0 = "/pico4-dtbo-sink/usb2_phy0";
		usb_nop_phy = "/pico4-dtbo-sink/usb_nop_phy";
		va_cdc_dma_0_tx = "/pico4-dtbo-sink/va_cdc_dma_0_tx";
		vendor = "/pico4-dtbo-sink/vendor";
		wcd938x_reset_active = "/pico4-dtbo-sink/wcd938x_reset_active";
		wcd938x_reset_sleep = "/pico4-dtbo-sink/wcd938x_reset_sleep";
		wdog = "/pico4-dtbo-sink/wdog";
		wil6210 = "/pico4-dtbo-sink/wil6210";
		wlan = "/pico4-dtbo-sink/wlan";
	};
};
